# ATmega128A register map
Vendor: Atmel; File version: 1.0
CPU: other r0p0, little endian, no MPU, no FPU, 4 interrupt priority bits
Registers are 8-bit, read-write, reset 0x0 unless marked. A register's access mark holds for its fields unless they carry their own. Offsets are from the block's base; [hi:lo] are bit positions.

## FUSE — Fuses
Base 0x00000000
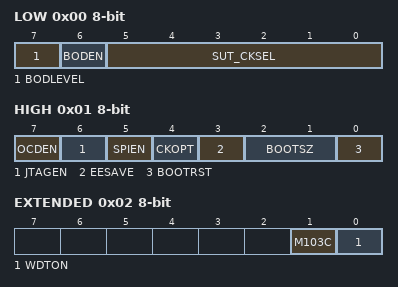
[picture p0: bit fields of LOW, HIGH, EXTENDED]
0x00 LOW
  [7] BODLEVEL — Brownout detector trigger level
    0=4V0 (Brown-out detection level at VCC=4.0 V); 1=2V7 (Brown-out detection level at VCC=2.7 V)
  [6] BODEN — Brown-out detection enabled
  [5:0] SUT_CKSEL — Select Clock Source
    0=EXTCLK_6CK_0MS (Ext. Clock; Start-up time: 6 CK + 0 ms); 1=INTRCOSC_1MHZ_6CK_0MS (Int. RC Osc. 1 MHz; Start-up time: 6 CK + 0 ms); 2=INTRCOSC_2MHZ_6CK_0MS (Int. RC Osc. 2 MHz; Start-up time: 6 CK + 0 ms); 3=INTRCOSC_4MHZ_6CK_0MS (Int. RC Osc. 4 MHz; Start-up time: 6 CK + 0 ms); 4=INTRCOSC_8MHZ_6CK_0MS (Int. RC Osc. 8 MHz; Start-up time: 6 CK + 0 ms); 5=EXTRCOSC_XX_0MHZ9_18CK_0MS (Ext. RC Osc. - 0.9 MHz; Start-up time: 18 CK + 0 ms); 6=EXTRCOSC_0MHZ9_3MHZ_18CK_0MS (Ext. RC Osc. 0.9 MHz - 3.0 MHz; Start-up time: 18 CK + 0 ms); 7=EXTRCOSC_3MHZ_8MHZ_18CK_0MS (Ext. RC Osc. 3.0 MHz - 8.0 MHz; Start-up time: 18 CK + 0 ms); 8=EXTRCOSC_8MHZ_12MHZ_18CK_0MS (Ext. RC Osc. 8.0 MHz - 12.0 MHz; Start-up time: 18 CK + 0 ms); 9=EXTLOFXTAL_1KCK_4MS (Ext. Low-Freq. Crystal; Start-up time: 1K CK + 4 ms); 10=EXTLOFXTALRES_258CK_4MS (Ext. Crystal/Resonator Low Freq.; Start-up time: 258 CK + 4 ms); 11=EXTLOFXTALRES_1KCK_64MS (Ext. Crystal/Resonator Low Freq.; Start-up time: 1K CK + 64 ms); 12=EXTMEDFXTALRES_258CK_4MS (Ext. Crystal/Resonator Medium Freq.; Start-up time: 258 CK + 4 ms); 13=EXTMEDFXTALRES_1KCK_64MS (Ext. Crystal/Resonator Medium Freq.; Start-up time: 1K CK + 64 ms); 14=EXTHIFXTALRES_258CK_4MS (Ext. Crystal/Resonator High Freq.; Start-up time: 258 CK + 4 ms); 15=EXTHIFXTALRES_1KCK_64MS (Ext. Crystal/Resonator High Freq.; Start-up time: 1K CK + 64 ms); 16=EXTCLK_6CK_4MS (Ext. Clock; Start-up time: 6 CK + 4 ms); 17=INTRCOSC_1MHZ_6CK_4MS (Int. RC Osc. 1 MHz; Start-up time: 6 CK + 4 ms); 18=INTRCOSC_2MHZ_6CK_4MS (Int. RC Osc. 2 MHz; Start-up time: 6 CK + 4 ms); 19=INTRCOSC_4MHZ_6CK_4MS (Int. RC Osc. 4 MHz; Start-up time: 6 CK + 4 ms); 20=INTRCOSC_8MHZ_6CK_4MS (Int. RC Osc. 8 MHz; Start-up time: 6 CK + 4 ms); 21=EXTRCOSC_XX_0MHZ9_18CK_4MS (Ext. RC Osc. - 0.9 MHz; Start-up time: 18 CK + 4 ms); 22=EXTRCOSC_0MHZ9_3MHZ_18CK_4MS (Ext. RC Osc. 0.9 MHz - 3.0 MHz; Start-up time: 18 CK + 4 ms); 23=EXTRCOSC_3MHZ_8MHZ_18CK_4MS (Ext. RC Osc. 3.0 MHz - 8.0 MHz; Start-up time: 18 CK + 4 ms); 24=EXTRCOSC_8MHZ_12MHZ_18CK_4MS (Ext. RC Osc. 8.0 MHz - 12.0 MHz; Start-up time: 18 CK + 4 ms); 25=EXTLOFXTAL_1KCK_64MS (Ext. Low-Freq. Crystal; Start-up time: 1K CK + 64 ms); 26=EXTLOFXTALRES_258CK_64MS (Ext. Crystal/Resonator Low Freq.; Start-up time: 258 CK + 64 ms); 27=EXTLOFXTALRES_16KCK_0MS (Ext. Crystal/Resonator Low Freq.; Start-up time: 16K CK + 0 ms); 28=EXTMEDFXTALRES_258CK_64MS (Ext. Crystal/Resonator Medium Freq.; Start-up time: 258 CK + 64 ms); 29=EXTMEDFXTALRES_16KCK_0MS (Ext. Crystal/Resonator Medium Freq.; Start-up time: 16K CK + 0 ms); 30=EXTHIFXTALRES_258CK_64MS (Ext. Crystal/Resonator High Freq.; Start-up time: 258 CK + 64 ms); 31=EXTHIFXTALRES_16KCK_0MS (Ext. Crystal/Resonator High Freq.; Start-up time: 16K CK + 0 ms); 32=EXTCLK_6CK_64MS (Ext. Clock; Start-up time: 6 CK + 64 ms); 33=INTRCOSC_1MHZ_6CK_64MS (Int. RC Osc. 1 MHz; Start-up time: 6 CK + 64 ms); 34=INTRCOSC_2MHZ_6CK_64MS (Int. RC Osc. 2 MHz; Start-up time: 6 CK + 64 ms); 35=INTRCOSC_4MHZ_6CK_64MS (Int. RC Osc. 4 MHz; Start-up time: 6 CK + 64 ms); 36=INTRCOSC_8MHZ_6CK_64MS (Int. RC Osc. 8 MHz; Start-up time: 6 CK + 64 ms); 37=EXTRCOSC_XX_0MHZ9_18CK_64MS (Ext. RC Osc. - 0.9 MHz; Start-up time: 18 CK + 64 ms); 38=EXTRCOSC_0MHZ9_3MHZ_18CK_64MS (Ext. RC Osc. 0.9 MHz - 3.0 MHz; Start-up time: 18 CK + 64 ms); 39=EXTRCOSC_3MHZ_8MHZ_18CK_64MS (Ext. RC Osc. 3.0 MHz - 8.0 MHz; Start-up time: 18 CK + 64 ms); 40=EXTRCOSC_8MHZ_12MHZ_18CK_64MS (Ext. RC Osc. 8.0 MHz - 12.0 MHz; Start-up time: 18 CK + 64 ms); 41=EXTLOFXTAL_32KCK_64MS (Ext. Low-Freq. Crystal; Start-up time: 32K CK + 64 ms); 42=EXTLOFXTALRES_1KCK_0MS (Ext. Crystal/Resonator Low Freq.; Start-up time: 1K CK + 0 ms); 43=EXTLOFXTALRES_16KCK_4MS (Ext. Crystal/Resonator Low Freq.; Start-up time: 16K CK + 4 ms); 44=EXTMEDFXTALRES_1KCK_0MS (Ext. Crystal/Resonator Medium Freq.; Start-up time: 1K CK + 0 ms); 45=EXTMEDFXTALRES_16KCK_4MS (Ext. Crystal/Resonator Medium Freq.; Start-up time: 16K CK + 4 ms); 46=EXTHIFXTALRES_1KCK_0MS (Ext. Crystal/Resonator High Freq.; Start-up time: 1K CK + 0 ms); 47=EXTHIFXTALRES_16KCK_4MS (Ext. Crystal/Resonator High Freq.; Start-up time: 16K CK + 4 ms); 53=EXTRCOSC_XX_0MHZ9_6CK_4MS (Ext. RC Osc. - 0.9 MHz; Start-up time: 6 CK + 4 ms); 54=EXTRCOSC_0MHZ9_3MHZ_6CK_4MS (Ext. RC Osc. 0.9 MHz - 3.0 MHz; Start-up time: 6 CK + 4 ms); 55=EXTRCOSC_3MHZ_8MHZ_6CK_4MS (Ext. RC Osc. 3.0 MHz - 8.0 MHz; Start-up time: 6 CK + 4 ms); 56=EXTRCOSC_8MHZ_12MHZ_6CK_4MS (Ext. RC Osc. 8.0 MHz - 12.0 MHz; Start-up time: 6 CK + 4 ms); 58=EXTLOFXTALRES_1KCK_4MS (Ext. Crystal/Resonator Low Freq.; Start-up time: 1K CK + 4 ms); 59=EXTLOFXTALRES_16KCK_64MS (Ext. Crystal/Resonator Low Freq.; Start-up time: 16K CK + 64 ms); 60=EXTMEDFXTALRES_1KCK_4MS (Ext. Crystal/Resonator Medium Freq.; Start-up time: 1K CK + 4 ms); 61=EXTMEDFXTALRES_16KCK_64MS (Ext. Crystal/Resonator Medium Freq.; Start-up time: 16K CK + 64 ms); 62=EXTHIFXTALRES_1KCK_4MS (Ext. Crystal/Resonator High Freq.; Start-up time: 1K CK + 4 ms); 63=EXTHIFXTALRES_16KCK_64MS (Ext. Crystal/Resonator High Freq.; Start-up time: 16K CK + 64 ms)
0x01 HIGH
  [7] OCDEN — On-Chip Debug Enabled
  [6] JTAGEN — JTAG Interface Enabled
  [5] SPIEN — Serial program downloading (SPI) enabled
  [4] CKOPT — CKOPT fuse (operation dependent of CKSEL fuses)
  [3] EESAVE — Preserve EEPROM through the Chip Erase cycle
  [2:1] BOOTSZ — Select Boot Size
    0=4096W_F000 (Boot Flash size=4096 words start address=$F000); 1=2048W_F800 (Boot Flashsize=2048 words start address=$F800); 2=1024W_FC00 (Boot Flash size=1024 words start address=$FC00); 3=512W_FE00 (Boot Flash size=512 words start address=$FE00)
  [0] BOOTRST — Boot Reset vector Enabled
0x02 EXTENDED
  [1] M103C — ATmega103 Compatibility Mode
  [0] WDTON — Watchdog Timer always on
